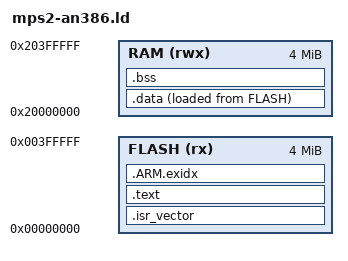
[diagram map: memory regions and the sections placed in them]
/* QEMU MPS2 AN386 (Cortex-M4): 4 MB of code memory at 0, 4 MB of RAM at 0x20000000. */
MEMORY
{
    FLASH (rx)  : ORIGIN = 0x00000000, LENGTH = 4M
    RAM   (rwx) : ORIGIN = 0x20000000, LENGTH = 4M
}

ENTRY(Reset_Handler)

SECTIONS
{
    .isr_vector : { KEEP(*(.isr_vector)) } > FLASH
    .text : {
        *(.text*)
        *(.rodata*)
        KEEP(*(.init)) KEEP(*(.fini))
        . = ALIGN(4);
        PROVIDE_HIDDEN(__preinit_array_start = .); KEEP(*(.preinit_array)) PROVIDE_HIDDEN(__preinit_array_end = .);
        PROVIDE_HIDDEN(__init_array_start = .); KEEP(*(SORT(.init_array.*))) KEEP(*(.init_array)) PROVIDE_HIDDEN(__init_array_end = .);
        PROVIDE_HIDDEN(__fini_array_start = .); KEEP(*(SORT(.fini_array.*))) KEEP(*(.fini_array)) PROVIDE_HIDDEN(__fini_array_end = .);
    } > FLASH
    .ARM.exidx : { *(.ARM.exidx* .gnu.linkonce.armexidx.*) } > FLASH

    _sidata = LOADADDR(.data);
    .data : { . = ALIGN(4); _sdata = .; *(.data*) . = ALIGN(4); _edata = .; } > RAM AT > FLASH
    .bss (NOLOAD) : { . = ALIGN(4); _sbss = .; *(.bss*) *(COMMON) . = ALIGN(4); _ebss = .; } > RAM

    end = .;                                   /* the C library's heap starts here */
    _end = .;
    _estack = ORIGIN(RAM) + LENGTH(RAM);
}
